# ESP32-S31 register map
Vendor: ESPRESSIF SYSTEMS (SHANGHAI) CO., LTD.; Series: ESP32 S-Series; File version: 1
CPU: RV32IMAFC r0p0, little endian, no MPU, FPU, 0 interrupt priority bits
Address unit: 32 bits
Registers are 32-bit, read-write, reset 0x0 unless marked. A register's access mark holds for its fields unless they carry their own. Offsets are from the block's base; [hi:lo] are bit positions; {n}, {i} and the like mark numbered series.

## RMA — RMA Peripheral
Base 0x2050F000
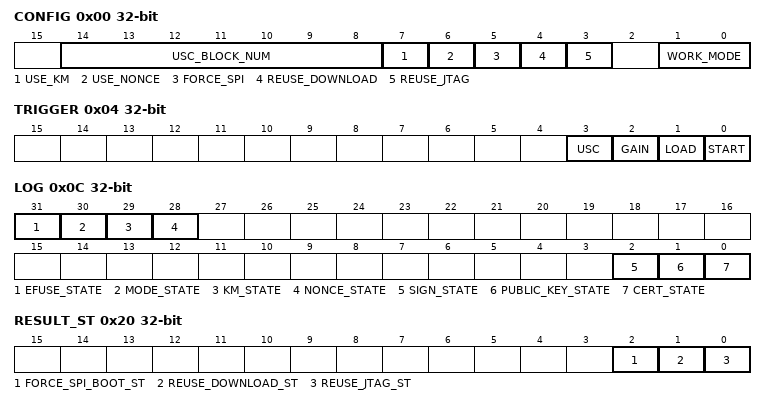
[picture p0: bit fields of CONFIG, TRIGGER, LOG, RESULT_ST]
0x00 CONFIG — Configures RMA algorithm
  [14:8] USC_BLOCK_NUM — The length of USC.
  [7] USE_KM — Whether use km to gnerate NONCE. \\ 0: Do not use KM to generate NONCE \\ 1: Use KM to generate NONCE\\
  [6] USE_NONCE — Whether use NONCE. \\ 0: Do not use NONCE\\ 1: Use NONCE\\
  [5] FORCE_SPI — Whether enable FORCE_SPI_BOOT after RMA pass. \\ 0: Do not enable FORCE_SPI_BOOT mode\\ 1: Enable FORCE_SPI_BOOT\\
  [4] REUSE_DOWNLOAD — Whether enable DOWNLOAD_MODE after RMA pass. \\ 0: Do not enable DOWNLOAD mode\\ 1: Enable DOWNLOAD\\
  [3] REUSE_JTAG — Whether enable JTAG after RMA pass. \\ 0: Do not enable JTAG \\ 1: Enable JTAG \\
  [1:0] WORK_MODE — Configures the RMA module. \\ 00: REQUEST CERTIFICATE\\ 01: VERIFICATION CERTIFICATE\\ 10: FAST VERIFICATION\\
0x04 TRIGGER wo — Starts the RMA module.
  [3] USC — Rma usc done. \\
  [2] GAIN — Rma gain done. \\
  [1] LOAD — Rma load done. \\
  [0] START — Start tigger typical rma. \\
0x08 STATE ro — query state in rma
  [2:0] STATE — The status bits of RMA Accelerator. RMA is at 0: IDLE, 1: LOAD, 2: GAIN, 3: USC, 4: LOCK, others: BUSY state.
0x0C LOG ro — Query result in rma
  [31] EFUSE_STATE — Marks efuse state . \\ 0 : Efuse disable RMA module\\ 1 : Efuse pass\\
  [30] MODE_STATE — Marks error mode config . \\ 0 : Invalid mode config\\ 1 : MODE config pass\\
  [29] KM_STATE — Marks error KM config . \\ 0 : Use km but km key invalid\\ 1 : KM config pass\\
  [28] NONCE_STATE — Marks error nonce config . \\ 0 : Use efuse_hash_sg in CERT_REQ or FAST_VEF but key invalid\\ 1 : Nonce config pass.
  [2] SIGN_STATE — Marks state of rma sign verification result. \\ 1: pass\\ 0: failed\\
  [1] PUBLIC_KEY_STATE — Marks state of rma public key verification result. \\ 1: pass\\ 0: failed\\
  [0] CERT_STATE — Marks state of rma cert verification result. \\ 1: pass\\ 0: failed\\
0x10 INT_RAW ro — RMA interrupt raw register, valid in level.
  [0] PROC_DONE_INT_RAW — The raw interrupt status bit for the rma_proc_done_int interrupt
0x14 INT_ST ro — RMA interrupt status register.
  [0] PROC_DONE_INT_ST — The masked interrupt status bit for the rma_proc_done_int interrupt
0x18 INT_ENA — RMA interrupt enable register.
  [0] PROC_DONE_INT_ENA — The interrupt enable bit for the rma_proc_done_int interrupt
0x1C INT_CLR wo — RMA interrupt clear register.
  [0] PROC_DONE_INT_CLR — Set this bit to clear the rma_proc_done_int interrupt
0x20 RESULT_ST ro — RMA result reg.
  [2] FORCE_SPI_BOOT_ST — The state of force spi boot reg register.
  [1] REUSE_DOWNLOAD_ST — The state of reuse download register.
  [0] REUSE_JTAG_ST — The state of reuse jtag register.
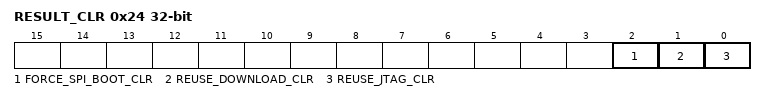
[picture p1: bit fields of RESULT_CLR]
0x24 RESULT_CLR wo — RMA clr result reg.
  [2] FORCE_SPI_BOOT_CLR — Set this bit to clear the force spi boot state.
  [1] REUSE_DOWNLOAD_CLR — Set this bit to clear the reuse download state.
  [0] REUSE_JTAG_CLR — Set this bit to clear the reuse jtag state.
0x28 TIMEOUT_LIMIT reset 0xFFFFFFFF — RMA timeout limit configurate register
  [31:0] TIMEOUT_LIMIT — The timeout limitation for waiting sub-IP.
0x7C DATE reset 0x20250819 — Version control register
  [31:0] DATE — Version control register.
{0x80+i} CHIP_INFO_SOURCE_MEM[{i}] (i=0..3) 8-bit access not given — RMA chip info memory.
{0x84+i} NONCE_MEM[{i}] (i=0..3) 8-bit access not given — RMA nonce memory.
{0x88+i} USC_MEM[{i}] (i=0..3) 8-bit access not given — RMA USC memory.
{0x8C+i} PUBLIC_KEY_MEM[{i}] (i=0..3) 8-bit access not given — RMA public key memory .
{0x90+i} SIGN_MEM[{i}] (i=0..3) 8-bit access not given — RMA signature r memory .
{0x94+i} CERT_HASH_MEM[{i}] (i=0..3) 8-bit access not given — RMA cert hash memory.
{0x98+i} CHIP_INFO_MEM[{i}] (i=0..3) 8-bit access not given — RMA chip info memory .
